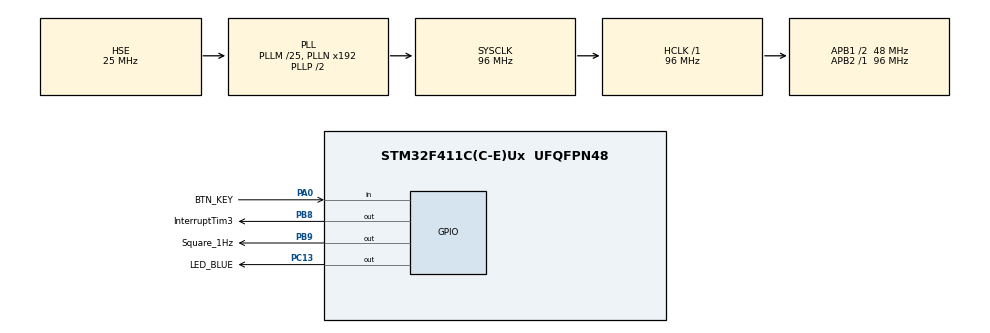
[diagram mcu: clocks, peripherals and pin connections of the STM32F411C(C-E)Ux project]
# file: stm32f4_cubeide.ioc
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Mcu.Family=STM32F4
Mcu.Name=STM32F411C(C-E)Ux
Mcu.Package=UFQFPN48
NVIC.PriorityGroup=NVIC_PRIORITYGROUP_4
NVIC.TIM3_IRQn=true\:0\:0\:false\:true\:true\:1\:true\:true\:true
PA0-WKUP.GPIO_Label=BTN_KEY
PA0-WKUP.GPIO_PuPd=GPIO_PULLUP
PA0-WKUP.Signal=GPIO_Input
PB8.GPIO_Label=InterruptTim3
PB8.GPIO_Speed=GPIO_SPEED_FREQ_VERY_HIGH
PB8.Signal=GPIO_Output
PB9.GPIO_Label=Square_1Hz
PB9.GPIO_Speed=GPIO_SPEED_FREQ_LOW
PB9.Signal=GPIO_Output
PC13-ANTI_TAMP.GPIO_Label=LED_BLUE
PC13-ANTI_TAMP.Signal=GPIO_Output
PH0\ -\ OSC_IN.Mode=HSE-External-Oscillator
PH0\ -\ OSC_IN.Signal=RCC_OSC_IN
PH1\ -\ OSC_OUT.Mode=HSE-External-Oscillator
PH1\ -\ OSC_OUT.Signal=RCC_OSC_OUT
ProjectManager.HeapSize=0x200
ProjectManager.StackSize=0x400
ProjectManager.TargetToolchain=STM32CubeIDE
RCC.48MHZClocksFreq_Value=48000000
RCC.AHBFreq_Value=96000000
RCC.APB1CLKDivider=RCC_HCLK_DIV2
RCC.APB1Freq_Value=48000000
RCC.APB1TimFreq_Value=96000000
RCC.APB2Freq_Value=96000000
RCC.APB2TimFreq_Value=96000000
RCC.CortexFreq_Value=96000000
RCC.HCLKFreq_Value=96000000
RCC.HSE_VALUE=25000000
RCC.HSI_VALUE=16000000
RCC.LSE_VALUE=32768
RCC.PLLM=25
RCC.PLLSourceVirtual=RCC_PLLSOURCE_HSE
RCC.SYSCLKFreq_VALUE=96000000
RCC.SYSCLKSource=RCC_SYSCLKSOURCE_PLLCLK
RCC.VCOOutputFreq_Value=192000000
TIM2.Period=0xFFFFFFFF
TIM2.Prescaler=96-1
TIM3.Period=48000-1
TIM3.Prescaler=1
VP_TIM2_VS_ClockSourceINT.Mode=Internal
VP_TIM3_VS_ClockSourceINT.Mode=Internal
board=custom

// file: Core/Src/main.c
/* USER CODE BEGIN Header */
/**
  ******************************************************************************
  * @file           : main.c
  * @brief          : Main program body
  ******************************************************************************
  * @attention
  *
  * Copyright (c) 2026 STMicroelectronics.
  * All rights reserved.
  *
  * This software is licensed under terms that can be found in the LICENSE file
  * in the root directory of this software component.
  * If no LICENSE file comes with this software, it is provided AS-IS.
  *
  ******************************************************************************
  */
/* USER CODE END Header */
#include "main.h"

TIM_HandleTypeDef htim2;
TIM_HandleTypeDef htim3;

void SystemClock_Config(void);
static void MX_GPIO_Init(void);
static void MX_TIM2_Init(void);
static void MX_TIM3_Init(void);
static void MX_NVIC_Init(void);
/* USER CODE BEGIN PFP */

void init_app(void);
int run_app(void);
void app_tim3_interrupt(void);

/* USER CODE END PFP */

/* USER CODE BEGIN 0 */
void HAL_TIM_PeriodElapsedCallback(TIM_HandleTypeDef *htim)
{
	if (htim->Instance == TIM3)
	{
		app_tim3_interrupt();
	}
}
/* USER CODE END 0 */

int main(void)
{

  /* MCU Configuration--------------------------------------------------------*/

  /* Reset of all peripherals, Initializes the Flash interface and the Systick. */
  HAL_Init();

  /* Configure the system clock */
  SystemClock_Config();

  /* Initialize all configured peripherals */
  MX_GPIO_Init();
  MX_TIM2_Init();
  MX_TIM3_Init();

  /* Initialize interrupts */
  MX_NVIC_Init();
  /* USER CODE BEGIN 2 */

  if (HAL_TIM_Base_Start_IT(&htim2) != HAL_OK)
  {
      Error_Handler();
  }

  init_app();

  if (HAL_TIM_Base_Start_IT(&htim3) != HAL_OK)
  {
      Error_Handler();
  }

  run_app();	// invoke the c++ application class

  /* USER CODE END 2 */

  /* Infinite loop */
  while(1)
  {

  }
}

void SystemClock_Config(void)
{
  RCC_OscInitTypeDef RCC_OscInitStruct = {0};
  RCC_ClkInitTypeDef RCC_ClkInitStruct = {0};

  /** Configure the main internal regulator output voltage
  */
  __HAL_RCC_PWR_CLK_ENABLE();
  __HAL_PWR_VOLTAGESCALING_CONFIG(PWR_REGULATOR_VOLTAGE_SCALE1);

  /** Initializes the RCC Oscillators according to the specified parameters
  * in the RCC_OscInitTypeDef structure.
  */
  RCC_OscInitStruct.OscillatorType = RCC_OSCILLATORTYPE_HSE;
  RCC_OscInitStruct.HSEState = RCC_HSE_ON;
  RCC_OscInitStruct.PLL.PLLState = RCC_PLL_ON;
  RCC_OscInitStruct.PLL.PLLSource = RCC_PLLSOURCE_HSE;
  RCC_OscInitStruct.PLL.PLLM = 25;
  RCC_OscInitStruct.PLL.PLLN = 192;
  RCC_OscInitStruct.PLL.PLLP = RCC_PLLP_DIV2;
  RCC_OscInitStruct.PLL.PLLQ = 4;
  if (HAL_RCC_OscConfig(&RCC_OscInitStruct) != HAL_OK)
  {
    Error_Handler();
  }

  /** Initializes the CPU, AHB and APB buses clocks
  */
  RCC_ClkInitStruct.ClockType = RCC_CLOCKTYPE_HCLK|RCC_CLOCKTYPE_SYSCLK
                              |RCC_CLOCKTYPE_PCLK1|RCC_CLOCKTYPE_PCLK2;
  RCC_ClkInitStruct.SYSCLKSource = RCC_SYSCLKSOURCE_PLLCLK;
  RCC_ClkInitStruct.AHBCLKDivider = RCC_SYSCLK_DIV1;
  RCC_ClkInitStruct.APB1CLKDivider = RCC_HCLK_DIV2;
  RCC_ClkInitStruct.APB2CLKDivider = RCC_HCLK_DIV1;

  if (HAL_RCC_ClockConfig(&RCC_ClkInitStruct, FLASH_LATENCY_3) != HAL_OK)
  {
    Error_Handler();
  }
}

/**
  * @brief NVIC Configuration.
  * @retval None
  */
static void MX_NVIC_Init(void)
{
  /* TIM3_IRQn interrupt configuration */
  HAL_NVIC_SetPriority(TIM3_IRQn, 0, 0);
  HAL_NVIC_EnableIRQ(TIM3_IRQn);
}

static void MX_TIM2_Init(void)
{

  TIM_ClockConfigTypeDef sClockSourceConfig = {0};
  TIM_MasterConfigTypeDef sMasterConfig = {0};

  htim2.Instance = TIM2;
  htim2.Init.Prescaler = 96-1;
  htim2.Init.CounterMode = TIM_COUNTERMODE_UP;
  htim2.Init.Period = 0xFFFFFFFF;
  htim2.Init.ClockDivision = TIM_CLOCKDIVISION_DIV1;
  htim2.Init.AutoReloadPreload = TIM_AUTORELOAD_PRELOAD_DISABLE;
  if (HAL_TIM_Base_Init(&htim2) != HAL_OK)
  {
    Error_Handler();
  }
  sClockSourceConfig.ClockSource = TIM_CLOCKSOURCE_INTERNAL;
  if (HAL_TIM_ConfigClockSource(&htim2, &sClockSourceConfig) != HAL_OK)
  {
    Error_Handler();
  }
  sMasterConfig.MasterOutputTrigger = TIM_TRGO_RESET;
  sMasterConfig.MasterSlaveMode = TIM_MASTERSLAVEMODE_DISABLE;
  if (HAL_TIMEx_MasterConfigSynchronization(&htim2, &sMasterConfig) != HAL_OK)
  {
    Error_Handler();
  }

}

static void MX_TIM3_Init(void)
{

  TIM_ClockConfigTypeDef sClockSourceConfig = {0};
  TIM_MasterConfigTypeDef sMasterConfig = {0};

  htim3.Instance = TIM3;
  htim3.Init.Prescaler = 1;
  htim3.Init.CounterMode = TIM_COUNTERMODE_UP;
  htim3.Init.Period = 48000-1;
  htim3.Init.ClockDivision = TIM_CLOCKDIVISION_DIV1;
  htim3.Init.AutoReloadPreload = TIM_AUTORELOAD_PRELOAD_DISABLE;
  if (HAL_TIM_Base_Init(&htim3) != HAL_OK)
  {
    Error_Handler();
  }
  sClockSourceConfig.ClockSource = TIM_CLOCKSOURCE_INTERNAL;
  if (HAL_TIM_ConfigClockSource(&htim3, &sClockSourceConfig) != HAL_OK)
  {
    Error_Handler();
  }
  sMasterConfig.MasterOutputTrigger = TIM_TRGO_RESET;
  sMasterConfig.MasterSlaveMode = TIM_MASTERSLAVEMODE_DISABLE;
  if (HAL_TIMEx_MasterConfigSynchronization(&htim3, &sMasterConfig) != HAL_OK)
  {
    Error_Handler();
  }

}

static void MX_GPIO_Init(void)
{
  GPIO_InitTypeDef GPIO_InitStruct = {0};

  /* GPIO Ports Clock Enable */
  __HAL_RCC_GPIOC_CLK_ENABLE();
  __HAL_RCC_GPIOH_CLK_ENABLE();
  __HAL_RCC_GPIOA_CLK_ENABLE();
  __HAL_RCC_GPIOB_CLK_ENABLE();

  /*Configure GPIO pin Output Level */
  HAL_GPIO_WritePin(LED_BLUE_GPIO_Port, LED_BLUE_Pin, GPIO_PIN_RESET);

  /*Configure GPIO pin Output Level */
  HAL_GPIO_WritePin(GPIOB, InterruptTim3_Pin|Square_1Hz_Pin, GPIO_PIN_RESET);

  /*Configure GPIO pin : LED_BLUE_Pin */
  GPIO_InitStruct.Pin = LED_BLUE_Pin;
  GPIO_InitStruct.Mode = GPIO_MODE_OUTPUT_PP;
  GPIO_InitStruct.Pull = GPIO_NOPULL;
  GPIO_InitStruct.Speed = GPIO_SPEED_FREQ_LOW;
  HAL_GPIO_Init(LED_BLUE_GPIO_Port, &GPIO_InitStruct);

  /*Configure GPIO pin : BTN_KEY_Pin */
  GPIO_InitStruct.Pin = BTN_KEY_Pin;
  GPIO_InitStruct.Mode = GPIO_MODE_INPUT;
  GPIO_InitStruct.Pull = GPIO_PULLUP;
  HAL_GPIO_Init(BTN_KEY_GPIO_Port, &GPIO_InitStruct);

  /*Configure GPIO pin : InterruptTim3_Pin */
  GPIO_InitStruct.Pin = InterruptTim3_Pin;
  GPIO_InitStruct.Mode = GPIO_MODE_OUTPUT_PP;
  GPIO_InitStruct.Pull = GPIO_NOPULL;
  GPIO_InitStruct.Speed = GPIO_SPEED_FREQ_VERY_HIGH;
  HAL_GPIO_Init(InterruptTim3_GPIO_Port, &GPIO_InitStruct);

  /*Configure GPIO pin : Square_1Hz_Pin */
  GPIO_InitStruct.Pin = Square_1Hz_Pin;
  GPIO_InitStruct.Mode = GPIO_MODE_OUTPUT_PP;
  GPIO_InitStruct.Pull = GPIO_NOPULL;
  GPIO_InitStruct.Speed = GPIO_SPEED_FREQ_LOW;
  HAL_GPIO_Init(Square_1Hz_GPIO_Port, &GPIO_InitStruct);

}

void Error_Handler(void)
{
  __disable_irq();
  while (1)
  {
  }
}
